AUTOSAR XML (schema 314)
package /ComponentType
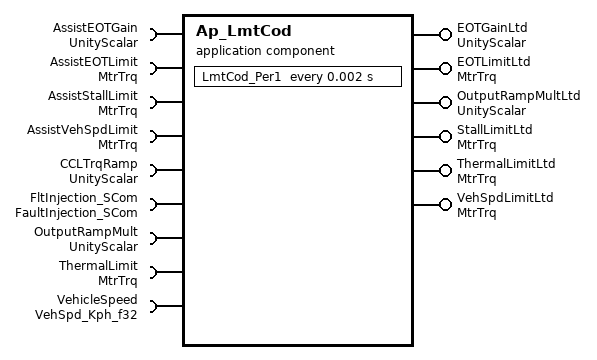
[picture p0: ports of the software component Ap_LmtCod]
  application software component type Ap_LmtCod
    6 x provide port:
      EOTGainLtd: unqueued-sender-com-spec{data-element=Uls_f32, can-invalidate=false, init-value=D_ONE_ULS_F32}, provided-interface=UnityScalar
      EOTLimitLtd: unqueued-sender-com-spec{data-element=MtrNm_f32, can-invalidate=false, init-value=D_MTRTRQCMDHILMT_MTRNM_F32}, provided-interface=MtrTrq
      OutputRampMultLtd: unqueued-sender-com-spec{data-element=Uls_f32, can-invalidate=false, init-value=D_ZERO_ULS_F32}, provided-interface=UnityScalar
      StallLimitLtd: unqueued-sender-com-spec{data-element=MtrNm_f32, can-invalidate=false, init-value=D_MTRTRQCMDHILMT_MTRNM_F32}, provided-interface=MtrTrq
      ThermalLimitLtd: unqueued-sender-com-spec{data-element=MtrNm_f32, can-invalidate=false, init-value=D_MTRTRQCMDHILMT_MTRNM_F32}, provided-interface=MtrTrq
      VehSpdLimitLtd: unqueued-sender-com-spec{data-element=MtrNm_f32, can-invalidate=false, init-value=D_MTRTRQCMDHILMT_MTRNM_F32}, provided-interface=MtrTrq
    9 x require port:
      AssistEOTGain: unqueued-receiver-com-spec{data-element=Uls_f32, init-value=D_ONE_ULS_F32}, required-interface=UnityScalar
      AssistEOTLimit: unqueued-receiver-com-spec{data-element=MtrNm_f32, init-value=D_MTRTRQCMDHILMT_MTRNM_F32}, required-interface=MtrTrq
      AssistStallLimit: unqueued-receiver-com-spec{data-element=MtrNm_f32, init-value=D_MTRTRQCMDHILMT_MTRNM_F32}, required-interface=MtrTrq
      AssistVehSpdLimit: unqueued-receiver-com-spec{data-element=MtrNm_f32, init-value=D_MTRTRQCMDHILMT_MTRNM_F32}, required-interface=MtrTrq
      CCLTrqRamp: unqueued-receiver-com-spec{data-element=Uls_f32, init-value=D_ONE_ULS_F32}, required-interface=UnityScalar
      FltInjection_SCom: client-com-spec=FltInjection, required-interface=FaultInjection_SCom
      OutputRampMult: unqueued-receiver-com-spec{data-element=Uls_f32, init-value=D_ZERO_ULS_F32}, required-interface=UnityScalar
      ThermalLimit: unqueued-receiver-com-spec{data-element=MtrNm_f32, init-value=D_MTRTRQCMDHILMT_MTRNM_F32}, required-interface=MtrTrq
      VehicleSpeed: unqueued-receiver-com-spec{data-element=Kph_f32, init-value=D_ZERO_ULS_F32}, required-interface=VehSpd_Kph_f32
  internal behavior Ap_LmtCod_InternalBehavior: component=Ap_LmtCod
    timing event TMT_LmtCod_Per1: start-on-event=LmtCod_Per1, period=0.002
    port-api-options:
      enable-take-address=false, indirect-api=false, port=AssistEOTGain
      enable-take-address=false, indirect-api=false, port=AssistEOTLimit
      enable-take-address=false, indirect-api=false, port=AssistStallLimit
      enable-take-address=false, indirect-api=false, port=AssistVehSpdLimit
      enable-take-address=false, indirect-api=false, port=CCLTrqRamp
      enable-take-address=false, indirect-api=false, port=EOTGainLtd
      enable-take-address=false, indirect-api=false, port=EOTLimitLtd
      enable-take-address=false, indirect-api=false, port=FltInjection_SCom
      enable-take-address=false, indirect-api=false, port=OutputRampMult
      enable-take-address=false, indirect-api=false, port=OutputRampMultLtd
      enable-take-address=false, indirect-api=false, port=StallLimitLtd
      enable-take-address=false, indirect-api=false, port=ThermalLimit
      enable-take-address=false, indirect-api=false, port=ThermalLimitLtd
      enable-take-address=false, indirect-api=false, port=VehicleSpeed
      enable-take-address=false, indirect-api=false, port=VehSpdLimitLtd
    runnable LmtCod_Per1
      8 x data read access:
        READ_AssistEOTGain_Uls_f32: data-element=AssistEOTGain.Uls_f32
        READ_AssistEOTLimit_MtrNm_f32: data-element=AssistEOTLimit.MtrNm_f32
        READ_AssistStallLimit_MtrNm_f32: data-element=AssistStallLimit.MtrNm_f32
        READ_AssistVehSpdLimit_MtrNm_f32: data-element=AssistVehSpdLimit.MtrNm_f32
        READ_CCLTrqRamp_Uls_f32: data-element=CCLTrqRamp.Uls_f32
        READ_OutputRampMult_Uls_f32: data-element=OutputRampMult.Uls_f32
        READ_ThermalLimit_MtrNm_f32: data-element=ThermalLimit.MtrNm_f32
        READ_VehicleSpeed_Kph_f32: data-element=VehicleSpeed.Kph_f32
      6 x data write access:
        WRITE_EOTGainLtd_Uls_f32: data-element=EOTGainLtd.Uls_f32
        WRITE_EOTLimitLtd_MtrNm_f32: data-element=EOTLimitLtd.MtrNm_f32
        WRITE_OutputRampMultLtd_Uls_f32: data-element=OutputRampMultLtd.Uls_f32
        WRITE_StallLimitLtd_MtrNm_f32: data-element=StallLimitLtd.MtrNm_f32
        WRITE_ThermalLimitLtd_MtrNm_f32: data-element=ThermalLimitLtd.MtrNm_f32
        WRITE_VehSpdLimitLtd_MtrNm_f32: data-element=VehSpdLimitLtd.MtrNm_f32
      sync call SC_FltInjection_SCom_FltInjection: operation=FltInjection_SCom.FltInjection, timeout=0
  swc implementation Ap_LmtCod_Implementation: behavior=Ap_LmtCod_InternalBehavior
    code-descriptors:
      code Code: type=SRC
